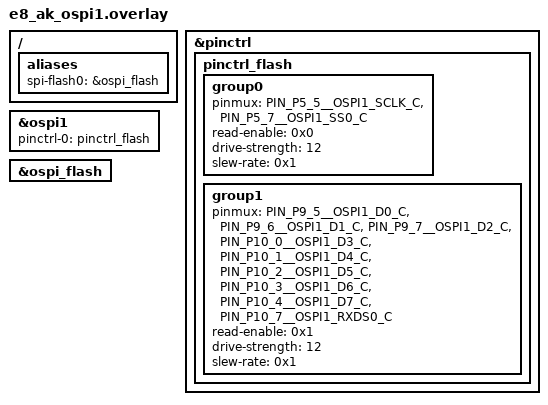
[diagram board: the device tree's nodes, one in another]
/* Copyright (C) 2026 Alif Semiconductor - All Rights Reserved.
 * Use, distribution and modification of this code is permitted under the
 * terms stated in the Alif Semiconductor Software License Agreement
 *
 * You should have received a copy of the Alif Semiconductor Software
 * License Agreement with this file. If not, please write to:
 * contact@alifsemi.com, or visit: https://alifsemi.com/license
 */

/*
 * OSPI1 Test with Flash
 */
/{
	aliases {
		spi-flash0 = &ospi_flash;
	};
};

&pinctrl {
	pinctrl_flash:pinctrl_flash {
		group0 {
			pinmux = <PIN_P5_5__OSPI1_SCLK_C>,
				 <PIN_P5_7__OSPI1_SS0_C>;
			read-enable = <0x0>;
			drive-strength = <12>;
			slew-rate = <0x1>;
		};
		group1 {
			pinmux = <PIN_P9_5__OSPI1_D0_C>,
				 <PIN_P9_6__OSPI1_D1_C>,
				 <PIN_P9_7__OSPI1_D2_C>,
				 <PIN_P10_0__OSPI1_D3_C>,
				 <PIN_P10_1__OSPI1_D4_C>,
				 <PIN_P10_2__OSPI1_D5_C>,
				 <PIN_P10_3__OSPI1_D6_C>,
				 <PIN_P10_4__OSPI1_D7_C>,
				 <PIN_P10_7__OSPI1_RXDS0_C>;
			read-enable = <0x1>;
			drive-strength = <12>;
			slew-rate = <0x1>;
		};
	};
};

&ospi1 {
	pinctrl-0 = <&pinctrl_flash>;
	status = "okay";
};

&ospi_flash {
	status = "okay";
};
